# APM32F411 register map
Vendor: Geehy; File version: 2024.11.05
CPU: CM4 r1p0, little endian, 3 interrupt priority bits
Registers are 32-bit, read-write, reset 0x0 unless marked. A register's access mark holds for its fields unless they carry their own. Offsets are from the block's base; [hi:lo] are bit positions; {n}, {i} and the like mark numbered series.

## UART4 — Universal synchronous asynchronous receiver transmitter
Base 0x40004C00
Same registers: UART5 0x40005000
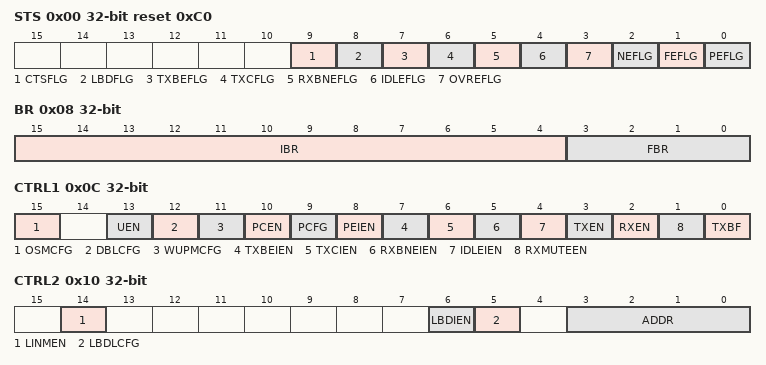
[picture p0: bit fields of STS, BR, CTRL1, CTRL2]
0x00 STS access per field reset 0xC0 — Status register
  [9] CTSFLG rw — CTS Change Flag
  [8] LBDFLG rw — LIN break detection flag
  [7] TXBEFLG ro — Transmit data register empty
  [6] TXCFLG rw — Transmission complete
  [5] RXBNEFLG rw — Read data register not empty
  [4] IDLEFLG ro — IDLE line detected
  [3] OVREFLG ro — Overrun error
  [2] NEFLG ro — Noise detected flag
  [1] FEFLG ro — Framing error
  [0] PEFLG ro — Parity error
0x04 DATA
  [8:0] DATA — Data value
0x08 BR — Baud rate register
  [15:4] IBR — mantissa of USARTDIV
  [3:0] FBR — fraction of USARTDIV
0x0C CTRL1 — Control register 1
  [15] OSMCFG — Oversampling mode
  [13] UEN — USART enable
  [12] DBLCFG — Word length
  [11] WUPMCFG — Wakeup method
  [10] PCEN — Parity control enable
  [9] PCFG — Parity selection
  [8] PEIEN — PE interrupt enable
  [7] TXBEIEN — TXE interrupt enable
  [6] TXCIEN — Transmission complete interrupt enable
  [5] RXBNEIEN — RXNE interrupt enable
  [4] IDLEIEN — IDLE interrupt enable
  [3] TXEN — Transmitter enable
  [2] RXEN — Receiver enable
  [1] RXMUTEEN — Receiver wakeup
  [0] TXBF — Send break
0x10 CTRL2 — Control register 2
  [14] LINMEN — LIN mode enable
  [6] LBDIEN — LIN break detection interrupt enable
  [5] LBDLCFG — lin break detection length
  [3:0] ADDR — Address of the USART node
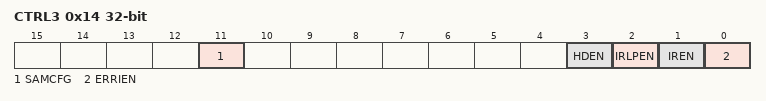
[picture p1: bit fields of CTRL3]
0x14 CTRL3 — Control register 3
  [11] SAMCFG — One sample bit method enable
  [3] HDEN — Half-duplex selection
  [2] IRLPEN — IrDA low-power
  [1] IREN — IrDA mode enable
  [0] ERRIEN — Error interrupt enable

## WWDT — Window watchdog
Base 0x40002C00
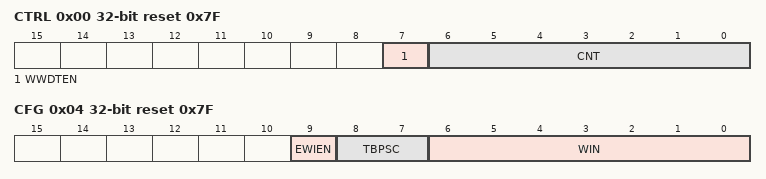
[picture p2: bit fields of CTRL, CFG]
0x00 CTRL reset 0x7F — Control register
  [7] WWDTEN — Activation bit
  [6:0] CNT — 7-bit counter (MSB to LSB)
0x04 CFG reset 0x7F — Configuration register
  [9] EWIEN — Early wakeup interrupt
  [8:7] TBPSC — Timer Base Prescaler Factor Configure
  [6:0] WIN — 7-bit window value
0x08 STS — Status register
  [0] EWIFLG — Early wakeup interrupt flag

## SCnSCB — System Controls not in SCB
Base 0xE000E000
0x04 ICTR ro — Interrupt Controller Type Register
  [3:0] INTLINESNUM — Indicates the number of interrupt lines implemented
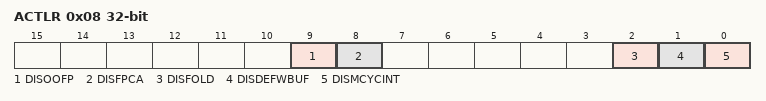
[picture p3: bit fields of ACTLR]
0x08 ACTLR — Auxiliary Control Register
  [9] DISOOFP — Disables out-of-order floating-point instruction completion
  [8] DISFPCA — Disables the FPCA bit in the CONTROL register
  [2] DISFOLD — Disables folding of IT instructions
  [1] DISDEFWBUF — Disables write buffer use during default memory map
  [0] DISMCYCINT — Disables interruption of multi-cycle instructions

## SysTick — System Tick Timer
Base 0xE000E010
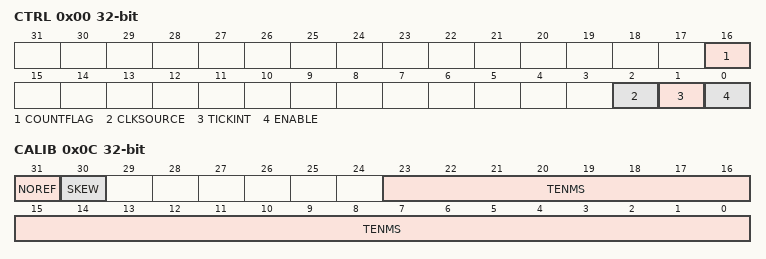
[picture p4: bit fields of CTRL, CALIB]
0x00 CTRL — SysTick Control and Status Register (aka SYST_CSR)
  [16] COUNTFLAG — Indicates if the counter reached 0
  [2] CLKSOURCE — Indicates the clock source
  [1] TICKINT — Enables the SysTick exception
  [0] ENABLE — Enables the counter
0x04 LOAD — SysTick Reload Value Register (aka SYST_RVR)
  [23:0] RELOAD — Value to load into the SysTick counter
0x08 VAL — SysTick Current Value Register (aka SYST_CVR)
  [23:0] CURRENT — Current value of the SysTick counter
0x0C CALIB ro — SysTick Calibration Register (aka SYST_CALIB)
  [31] NOREF — Indicates whether the reference clock is implemented
  [30] SKEW — Indicates whether the calibration value is exact
  [23:0] TENMS — Indicates the number of clock cycles for 10ms

## ITM — Instrumentation Trace Macrocell
Base 0xE0000000
{0x0+4i} STIM{i} (i=0..31) wo reset not defined — ITM Stimulus Port Registers (aka ITM_STIMx)
  [31:0] STIMULUS — Data written to the stimulus port
0xE00 TER — ITM Trace Enable Register (aka ITM_TERx)
  [31:0] STIMENA — Trace enable bits for each stimulus port
0xE40 TPR — ITM Trace Privilege Register
  [31:0] PRIVMASK — Privilege mask for access control
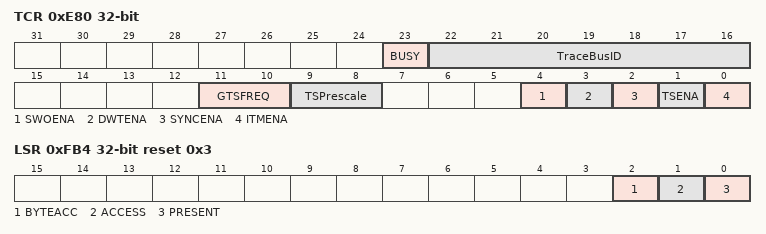
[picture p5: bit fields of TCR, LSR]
0xE80 TCR — ITM Trace Control Register
  [23] BUSY — Indicates if ITM is busy
  [22:16] TraceBusID
  [11:10] GTSFREQ — Global timestamp frequency
  [9:8] TSPrescale — Timestamp prescaler
  [4] SWOENA — SWO output enable
  [3] DWTENA — DWT event enable (aka TXENA)
  [2] SYNCENA — Synchronization enable
  [1] TSENA — Timestamp enable
  [0] ITMENA — ITM enable
0xFB0 LAR wo — ITM Lock Access Register
  [31:0] ACCESS — Write access to unlock ITM
0xFB4 LSR ro reset 0x3 — ITM Lock Status Register
  [2] BYTEACC — Indicates byte access capability
  [1] ACCESS — Indicates access status
  [0] PRESENT — Indicates ITM presence
{0xFD0+4i} PID{i} (i=0..7) ro (reset mask 0xFFFFFF00) — Peripheral Identification Registers
  [31:0] VALUE — Peripheral identification value
{0xFF0+4i} CID{i} (i=0..3) ro (reset mask 0xFFFFFF00) — Component Identification Registers
  [31:0] VALUE — Component identification value
